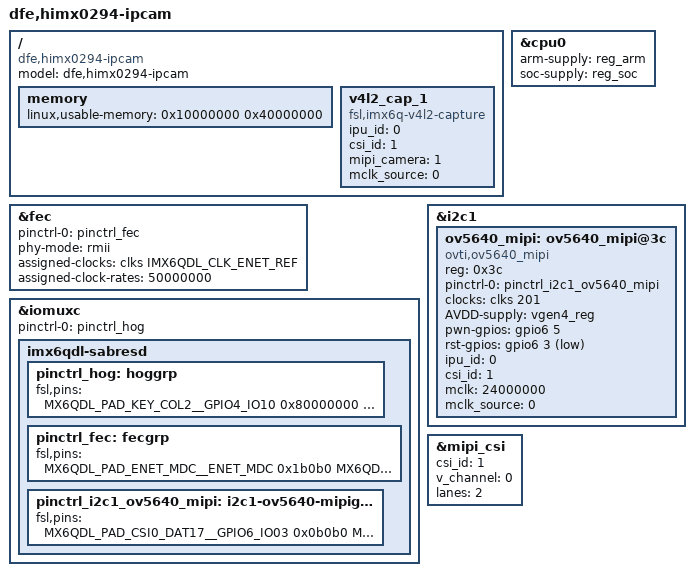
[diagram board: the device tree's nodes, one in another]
/*
 * Copyright 2012 Freescale Semiconductor, Inc.
 * Copyright 2011 Linaro Ltd.
 *
 * The code contained herein is licensed under the GNU General Public
 * License. You may obtain a copy of the GNU General Public License
 * Version 2 or later at the following locations:
 *
 * http://www.opensource.org/licenses/gpl-license.html
 * http://www.gnu.org/copyleft/gpl.html
 */

/dts-v1/;

#include "imx6q.dtsi"
#include "imx6qscm-himx0294-ipcam.dtsi"

/ {
	model = "dfe,himx0294-ipcam";
	compatible = "dfe,himx0294-ipcam", "fsl,imx6q";

	memory: memory {
	    linux,usable-memory = <0x10000000 0x40000000>;
	};

	v4l2_cap_1 {
		compatible = "fsl,imx6q-v4l2-capture";
		ipu_id = <0>;
		csi_id = <1>;
		mipi_camera = <1>;
		mclk_source = <0>;
		status = "okay";
	};

};

&cpu0 {
	arm-supply = <&reg_arm>;
	soc-supply = <&reg_soc>;
};

&fec {
	pinctrl-names = "default";
	pinctrl-0 = <&pinctrl_fec>;
	phy-mode = "rmii";
	assigned-clocks = <&clks IMX6QDL_CLK_ENET_REF >;
	assigned-clock-rates = <50000000>;
	status = "okay";
};

&iomuxc {
	pinctrl-names = "default";
	pinctrl-0 = <&pinctrl_hog>;

	imx6qdl-sabresd {
		pinctrl_hog: hoggrp {
			fsl,pins = <

				MX6QDL_PAD_KEY_COL2__GPIO4_IO10 0x80000000
				MX6QDL_PAD_EIM_EB2__GPIO2_IO30 0x80000000
				MX6QDL_PAD_CSI0_MCLK__CCM_CLKO1    0x130b0


/*
				MX6QDL_PAD_EIM_D22__GPIO3_IO22  0x80000000
				MX6QDL_PAD_NANDF_D0__GPIO2_IO00 0x80000000
				MX6QDL_PAD_NANDF_CS1__GPIO6_IO14 0x80000000
				MX6QDL_PAD_NANDF_CS2__GPIO6_IO15 0x80000000
				MX6QDL_PAD_NANDF_D0__GPIO2_IO00 0x80000000
				MX6QDL_PAD_NANDF_D1__GPIO2_IO01 0x80000000
				//MX6QDL_PAD_GPIO_0__CCM_CLKO1    0x130b0
				MX6QDL_PAD_NANDF_CLE__GPIO6_IO07 0x80000000
				MX6QDL_PAD_NANDF_ALE__GPIO6_IO08 0x80000000
				MX6QDL_PAD_ENET_TXD1__GPIO1_IO29 0x80000000
				MX6QDL_PAD_EIM_D22__GPIO3_IO22  0x80000000
				MX6QDL_PAD_ENET_CRS_DV__GPIO1_IO25 0x80000000
				MX6QDL_PAD_EIM_D26__GPIO3_IO26 0x80000000
				MX6QDL_PAD_EIM_CS1__GPIO2_IO24 0x80000000
				MX6QDL_PAD_ENET_RXD0__GPIO1_IO27 0x80000000
				MX6QDL_PAD_EIM_A25__GPIO5_IO02 0x80000000
				MX6QDL_PAD_EIM_D23__GPIO3_IO23 0x80000000
				MX6QDL_PAD_EIM_EB3__GPIO2_IO31 0x80000000
				MX6QDL_PAD_SD3_RST__GPIO7_IO08	0x80000000
				MX6QDL_PAD_GPIO_9__GPIO1_IO09 	0x80000000
				MX6QDL_PAD_EIM_DA9__GPIO3_IO09 0x80000000
				MX6QDL_PAD_SD1_DAT3__WDOG2_B 0x80000000
				MX6QDL_PAD_NANDF_CS0__GPIO6_IO11 0x80000000
				//MX6QDL_PAD_NANDF_CS1__GPIO6_IO14 0x80000000
				MX6QDL_PAD_NANDF_CS2__GPIO6_IO15 0x80000000
				MX6QDL_PAD_GPIO_4__GPIO1_IO04   0x80000000
				MX6QDL_PAD_GPIO_2__GPIO1_IO02   0x80000000
				MX6QDL_PAD_EIM_EB2__GPIO2_IO30 0x80000000
				MX6QDL_PAD_NANDF_CS0__GPIO6_IO11 0x80000000
				//TOUCH RESET
				MX6QDL_PAD_KEY_COL2__GPIO4_IO10 0x80000000
				//TOUCH_INTERRUPT
				MX6QDL_PAD_NANDF_CS1__GPIO6_IO14 0x80000000

//				//camera
//				MX6QDL_PAD_GPIO_0__GPIO1_IO00  		  0x10881 //0x13059//0x10881
				//MX6QDL_PAD_CSI0_DAT19__GPIO6_IO05       0x80000000//0x17059//0x10881
*/
			>;
		};
		pinctrl_fec: fecgrp {
			fsl,pins = <
				MX6QDL_PAD_ENET_MDC__ENET_MDC		0x1b0b0
				MX6QDL_PAD_ENET_MDIO__ENET_MDIO		0x1b0b0
				MX6QDL_PAD_ENET_CRS_DV__ENET_RX_EN	0x1b0b0
				MX6QDL_PAD_ENET_RX_ER__ENET_RX_ER	0x1b0b0
				MX6QDL_PAD_ENET_TX_EN__ENET_TX_EN	0x1b0b0
				MX6QDL_PAD_ENET_RXD0__ENET_RX_DATA0	0x1b0b0
				MX6QDL_PAD_ENET_RXD1__ENET_RX_DATA1	0x1b0b0
				MX6QDL_PAD_ENET_TXD0__ENET_TX_DATA0	0x1b0b0
				MX6QDL_PAD_ENET_TXD1__ENET_TX_DATA1	0x1b0b0
				MX6QDL_PAD_GPIO_16__ENET_REF_CLK	0x4001b0a8
			>;
		};
		pinctrl_i2c1_ov5640_mipi: i2c1-ov5640-mipigrp {
			fsl,pins = <
				MX6QDL_PAD_CSI0_DAT17__GPIO6_IO03	0x0b0b0
				MX6QDL_PAD_CSI0_DAT19__GPIO6_IO05	0x000b0
			>;
		};

	};
};

&i2c1 {
	ov5640_mipi: ov5640_mipi@3c {
		compatible = "ovti,ov5640_mipi";
		reg = <0x3c>;
		pinctrl-names = "default";
		pinctrl-0 = <&pinctrl_i2c1_ov5640_mipi>;
		clocks = <&clks 201>;
		clock-names = "csi_mclk";
//		DOVDD-supply = <&vgen4_reg>; /* 1.8v */
		AVDD-supply = <&vgen4_reg>;  /* 2.8v, rev C board is VGEN3
						rev B board is VGEN5 */
//		DVDD-supply = <&vgen2_reg>;  /* 1.5v*/
		pwn-gpios = <&gpio6 5 GPIO_ACTIVE_HIGH>;
		rst-gpios = <&gpio6 3 GPIO_ACTIVE_LOW>;
		ipu_id = <0>;
		csi_id = <1>;
		mclk = <24000000>;
		mclk_source = <0>;
	};
};

&mipi_csi {
	status = "okay";
	csi_id = <1>;
	v_channel = <0>;
	lanes = <2>;
};

